# STMP3770 register map
Vendor: Freescale Semiconductor (NXP); Series: STMP37xx; File version: 1.0
CPU: other r0p0, little endian, no MPU, no FPU, 2 interrupt priority bits
Registers are 32-bit, read-write, reset 0x0 unless marked. A register's access mark holds for its fields unless they carry their own. Offsets are from the block's base; [hi:lo] are bit positions; {n}, {i} and the like mark numbered series.

## DIGCTL — STMP3770 DIGCTL 外设（数字控制/杂项）寄存器与位域中文描述。覆盖 slice 中全部寄存器与位域，名称逐字一致。
Base 0x8001C000
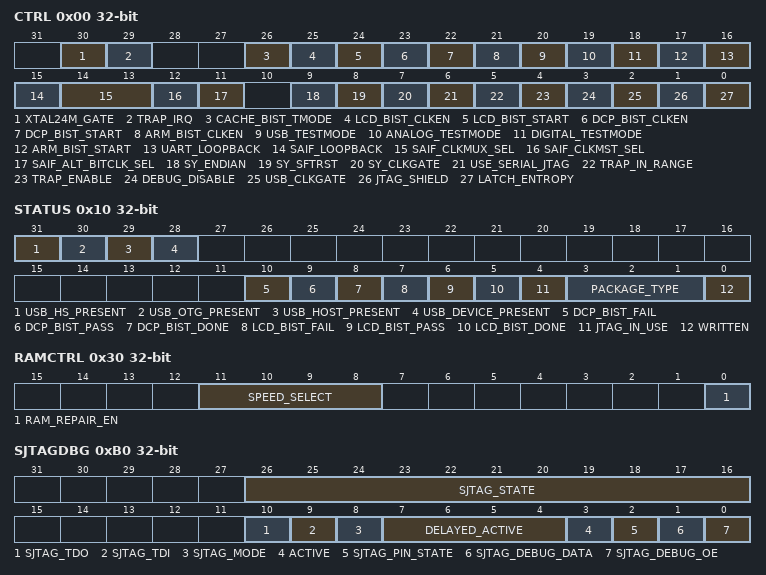
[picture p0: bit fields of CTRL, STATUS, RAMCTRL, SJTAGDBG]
0x00 CTRL — DIGCTL 控制寄存器，包含熵锁存、JTAG 防护、USB/SY 时钟门控、调试禁用、地址陷阱、串行 JTAG、SAIF/UART 环回、BIST 启动与时钟使能、测试模式、24MHz 晶振门控等控制位。
  [30] XTAL24M_GATE — 24MHz 晶振时钟门控控制位，置位关闭 XTAL24M 输出。
  [29] TRAP_IRQ — 地址陷阱中断状态/触发位。
  [26] CACHE_BIST_TMODE — Cache BIST 测试模式选择控制位。
  [25] LCD_BIST_CLKEN — LCD BIST 测试时钟使能控制位。
  [24] LCD_BIST_START — 置位启动 LCD 控制器 BIST。 PDF第7章标记bit 24为保留。
  [23] DCP_BIST_CLKEN — DCP BIST 测试时钟使能控制位。
  [22] DCP_BIST_START — 置位启动 DCP（显示协处理器）BIST。
  [21] ARM_BIST_CLKEN — ARM BIST 测试时钟使能控制位。
  [20] USB_TESTMODE — USB 测试模式使能控制位。
  [19] ANALOG_TESTMODE — 模拟测试模式使能控制位。
  [18] DIGITAL_TESTMODE — 数字测试模式使能控制位。
  [17] ARM_BIST_START — 置位启动 ARM 内核 BIST（内置自测试）。
  [16] UART_LOOPBACK — UART 环回模式：NORMAL=正常传输，LOOPIT=内部环回测试。
    0=NORMAL; 1=LOOPIT
  [15] SAIF_LOOPBACK — SAIF 环回模式：NORMAL=正常传输，LOOPIT=内部环回测试。
    0=NORMAL; 1=LOOPIT
  [14:13] SAIF_CLKMUX_SEL — SAIF 时钟多路选择：MBL_CLK_OUT/BL_CLK_OUT/M_CLK_OUT_BL_CLK_IN/BL_CLK_IN。
    0=MBL_CLK_OUT; 1=BL_CLK_OUT; 2=M_CLK_OUT_BL_CLK_IN; 3=BL_CLK_IN
  [12] SAIF_CLKMST_SEL — SAIF 主时钟源选择：SAIF1_MST=SAIF1 作主控，SAIF2_MST=SAIF2 作主控。
    0=SAIF1_MST; 1=SAIF2_MST
  [11] SAIF_ALT_BITCLK_SEL — SAIF 备用位时钟选择控制位。
  [9] SY_ENDIAN — SY 模块字节序选择控制位。 PDF第7章标记bit 9为保留。
  [8] SY_SFTRST — SY 模块软复位控制位。 PDF第7章标记bit 8为保留。
  [7] SY_CLKGATE — SY 模块时钟门控控制位。 PDF第7章标记bit 7为保留。
  [6] USE_SERIAL_JTAG — JTAG 接口选择：OLD_JTAG=传统 JTAG 接口，SERIAL_JTAG=串行 JTAG 接口。
    0=OLD_JTAG; 1=SERIAL_JTAG
  [5] TRAP_IN_RANGE — 置位表示陷阱范围有效（在 LOW/HIGH 地址之间），清零表示仅匹配单一地址。
  [4] TRAP_ENABLE — 使能地址陷阱功能，当访问落在陷阱范围内时触发异常。
  [3] DEBUG_DISABLE — 置位后禁用片上调试功能。
  [2] USB_CLKGATE — USB 控制器时钟门控：RUN=时钟运行，NO_CLKS=关闭时钟以节省功耗。
    0=RUN; 1=NO_CLKS
  [1] JTAG_SHIELD — JTAG 防护使能：NORMAL=正常模式，SHIELDS_UP=屏蔽模式（禁止外部 JTAG 访问）。
    0=NORMAL; 1=SHIELDS_UP
  [0] LATCH_ENTROPY — 置位后锁存当前 ENTROPY 寄存器值到 ENTROPY_LATCHED 寄存器。
0x10 STATUS ro — DIGCTL 状态寄存器，反映芯片封装类型、JTAG 占用状态、LCD/DCP BIST 结果及 USB 设备/主机/OTG/HS 存在性标志。
  [31] USB_HS_PRESENT — USB High-Speed 功能存在标志位。
  [30] USB_OTG_PRESENT — USB OTG 功能存在标志位。
  [29] USB_HOST_PRESENT — USB Host 功能存在标志位。
  [28] USB_DEVICE_PRESENT — USB Device 功能存在标志位。
  [10] DCP_BIST_FAIL — DCP BIST 测试失败标志位。
  [9] DCP_BIST_PASS — DCP BIST 测试通过标志位。
  [8] DCP_BIST_DONE — DCP BIST 测试完成标志位。
  [7] LCD_BIST_FAIL — LCD BIST 测试失败标志位。
  [6] LCD_BIST_PASS — LCD BIST 测试通过标志位。
  [5] LCD_BIST_DONE — LCD BIST 测试完成标志位。
  [4] JTAG_IN_USE — JTAG 接口当前正在被使用标志位。
  [3:1] PACKAGE_TYPE — 芯片封装类型标识编码。
  [0] WRITTEN — 芯片是否已被写入过（如熔丝/ROM 配置已写入）标志位。
0x20 HCLKCOUNT — HCLK 自由运行计数器，提供 32 位 AHB 总线时钟周期计数。
  [31:0] COUNT — HCLK 自由运行计数值，每拍递增，自然回绕。
0x30 RAMCTRL — 片内 RAM 控制寄存器，包含 RAM 修复使能与速度档位选择。
  [11:8] SPEED_SELECT — 片内 RAM 速度档位选择，用于调整时序裕量。
  [0] RAM_REPAIR_EN — 片内 RAM 修复功能使能控制位。
0x40 RAMREPAIR — 片内 RAM 修复地址寄存器，指定需要修复的 RAM 地址。
  [15:0] ADDR — RAM 修复目标地址。
0x50 ROMCTRL — 片内 ROM 控制寄存器，用于调整 ROM 读时序。
  [3:0] RD_MARGIN — ROM 读操作裕量（延迟/边距）设置值。
0x60 WRITEONCE — 软件一次性写寄存器，写入后不可再次修改（仅能在复位后重写）。
  [31:0] BITS — 32 位一次性写入数据位域。
0x90 ENTROPY — 熵寄存器，提供来自物理噪声源的随机数值。
  [31:0] VALUE — 实时熵值（随机数），由片上物理噪声源生成。
0xA0 ENTROPY_LATCHED — 熵锁存寄存器，保存由 LATCH_ENTROPY 触发锁存时的熵值。
  [31:0] VALUE — 锁存后的熵值快照，供软件读取固定随机数。
0xB0 SJTAGDBG — 串行 JTAG 调试寄存器，提供 SJTAG 接口的调试访问、状态监控与手动控制。
  [26:16] SJTAG_STATE — SJTAG 状态机当前状态编码。
  [10] SJTAG_TDO — SJTAG TDO（测试数据输出）信号值。
  [9] SJTAG_TDI — SJTAG TDI（测试数据输入）信号值。
  [8] SJTAG_MODE — SJTAG 模式选择控制位。
  [7:4] DELAYED_ACTIVE — SJTAG 激活延迟计数/延迟值。
  [3] ACTIVE — SJTAG 接口当前激活状态标志。
  [2] SJTAG_PIN_STATE — SJTAG 引脚当前状态。
  [1] SJTAG_DEBUG_DATA — SJTAG 调试数据输出值。
  [0] SJTAG_DEBUG_OE — SJTAG 调试数据输出使能控制位。
0xC0 MICROSECONDS — 微秒计数器寄存器，用于软件实现微秒级延时与计时。
  [31:0] VALUE — 微秒计数值，软件可读写，用于实现 us 级延时。
0xD0 DBGRD — 数字控制调试读测试寄存器，读取值为 DBG 寄存器值的按位取反。
  [31:0] COMPLEMENT — DBG 寄存器值的按位补码（取反），用于总线读测试验证。
0xE0 DBG — 数字控制调试寄存器，通用 32 位调试端口。
  [31:0] VALUE — 32 位调试数据值，只读，返回当前调试端口状态。
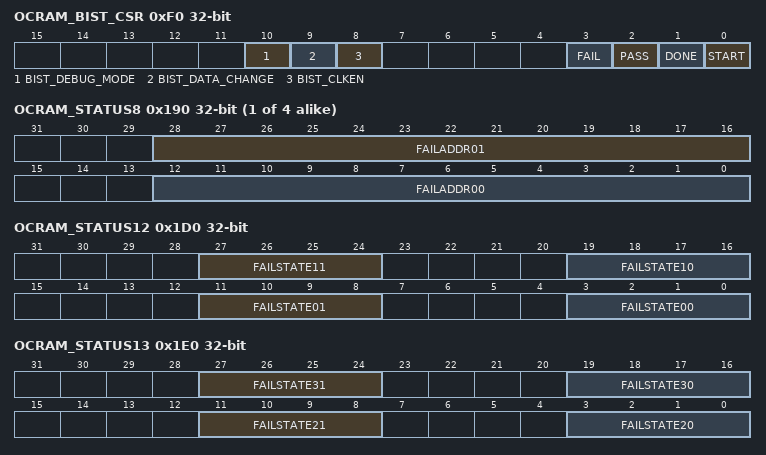
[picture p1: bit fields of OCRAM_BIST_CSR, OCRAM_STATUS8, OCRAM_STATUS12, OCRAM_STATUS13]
0xF0 OCRAM_BIST_CSR — SRAM BIST 控制与状态寄存器，用于启动和监控片内 SRAM 自测试。
  [10] BIST_DEBUG_MODE — SRAM BIST 调试模式使能控制位。
  [9] BIST_DATA_CHANGE — SRAM BIST 数据变化模式控制位。
  [8] BIST_CLKEN — SRAM BIST 测试时钟使能控制位。
  [3] FAIL — SRAM BIST 测试失败标志位。
  [2] PASS — SRAM BIST 测试通过标志位。
  [1] DONE — SRAM BIST 测试完成标志位。
  [0] START — 置位启动 SRAM BIST 测试。
0x110 OCRAM_STATUS0 — SRAM 状态寄存器 0，记录 BIST 失败时端口 0/数据 0 的故障数据。
  [31:0] FAILDATA00 — BIST 失败时端口 0、数据 0 的故障数据值。
0x120 OCRAM_STATUS1 — SRAM 状态寄存器 1，记录 BIST 失败时端口 0/数据 1 的故障数据。
  [31:0] FAILDATA01 — BIST 失败时端口 0、数据 1 的故障数据值。
0x130 OCRAM_STATUS2 — SRAM 状态寄存器 2，记录 BIST 失败时端口 1/数据 0 的故障数据。
  [31:0] FAILDATA10 — BIST 失败时端口 1、数据 0 的故障数据值。
0x140 OCRAM_STATUS3 — SRAM 状态寄存器 3，记录 BIST 失败时端口 1/数据 1 的故障数据。
  [31:0] FAILDATA11 — BIST 失败时端口 1、数据 1 的故障数据值。
0x150 OCRAM_STATUS4 — SRAM 状态寄存器 4，记录 BIST 失败时端口 2/数据 0 的故障数据。
  [31:0] FAILDATA20 — BIST 失败时端口 2、数据 0 的故障数据值。
0x160 OCRAM_STATUS5 — SRAM 状态寄存器 5，记录 BIST 失败时端口 2/数据 1 的故障数据。
  [31:0] FAILDATA21 — BIST 失败时端口 2、数据 1 的故障数据值。
0x170 OCRAM_STATUS6 — SRAM 状态寄存器 6，记录 BIST 失败时端口 3/数据 0 的故障数据。
  [31:0] FAILDATA30 — BIST 失败时端口 3、数据 0 的故障数据值。
0x180 OCRAM_STATUS7 — SRAM 状态寄存器 7，记录 BIST 失败时端口 3/数据 1 的故障数据。
  [31:0] FAILDATA31 — BIST 失败时端口 3、数据 1 的故障数据值。
{0x110+0x10*i} OCRAM_STATUS{i} (i=8..11) — SRAM 状态寄存器 {i}，记录 BIST 失败时端口 {i-8} 的故障地址。
  [28:16] FAILADDR{10i-79:02} — BIST 失败时端口 {i-8}、数据 1 的故障地址。
  [12:0] FAILADDR{10i-80:02} — BIST 失败时端口 {i-8}、数据 0 的故障地址。
0x1D0 OCRAM_STATUS12 — SRAM 状态寄存器 12，记录 BIST 失败时端口 0 和端口 1 的故障状态。
  [27:24] FAILSTATE11 — BIST 失败时端口 1、数据 1 的故障状态编码。
  [19:16] FAILSTATE10 — BIST 失败时端口 1、数据 0 的故障状态编码。
  [11:8] FAILSTATE01 — BIST 失败时端口 0、数据 1 的故障状态编码。
  [3:0] FAILSTATE00 — BIST 失败时端口 0、数据 0 的故障状态编码。
0x1E0 OCRAM_STATUS13 — SRAM 状态寄存器 13，记录 BIST 失败时端口 2 和端口 3 的故障状态。
  [27:24] FAILSTATE31 — BIST 失败时端口 3、数据 1 的故障状态编码。
  [19:16] FAILSTATE30 — BIST 失败时端口 3、数据 0 的故障状态编码。
  [11:8] FAILSTATE21 — BIST 失败时端口 2、数据 1 的故障状态编码。
  [3:0] FAILSTATE20 — BIST 失败时端口 2、数据 0 的故障状态编码。
0x290 SCRATCH0 — 数字控制 scratch 寄存器 0，供软件临时存储 32 位数据。
  [31:0] PTR — 32 位通用暂存数据值。
0x2A0 SCRATCH1 — 数字控制 scratch 寄存器 1，供软件临时存储 32 位数据。
  [31:0] PTR — 32 位通用暂存数据值。
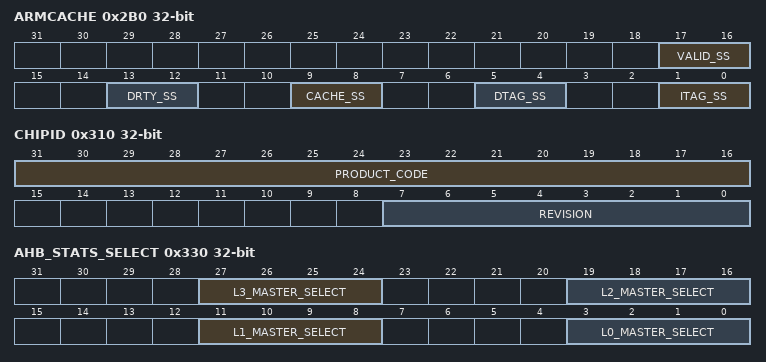
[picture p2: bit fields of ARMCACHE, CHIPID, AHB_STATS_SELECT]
0x2B0 ARMCACHE — ARM Cache 寄存器，反映 ARM926EJ-S 各 cache 子阵列的大小配置状态。
  [17:16] VALID_SS — Valid 位阵列大小状态（Valid sub-array size status）。
  [13:12] DRTY_SS — Dirty 位阵列大小状态（Dirty sub-array size status）。
  [9:8] CACHE_SS — Cache 数据阵列大小状态（Cache sub-array size status）。
  [5:4] DTAG_SS — 数据 Tag 阵列大小状态（DTAG sub-array size status）。
  [1:0] ITAG_SS — 指令 Tag 阵列大小状态（ITAG sub-array size status）。
0x2C0 DEBUG_TRAP_ADDR_LOW — 调试陷阱范围低地址寄存器，设定地址陷阱监控范围的下限。
  [31:0] ADDR — 陷阱范围低地址边界值。
0x2D0 DEBUG_TRAP_ADDR_HIGH — 调试陷阱范围高地址寄存器，设定地址陷阱监控范围的上限。
  [31:0] ADDR — 陷阱范围高地址边界值。
0x300 SGTL — SigmaTel 版权标识寄存器，读取返回固定版权标识码。
  [31:0] COPYRIGHT — SigmaTel 版权标识值。
0x310 CHIPID — 芯片版本与产品代码寄存器，用于识别芯片型号与硅片版本。
  [31:16] PRODUCT_CODE — 芯片产品代码，用于区分不同型号/变体。
  [7:0] REVISION — 芯片硅片版本号（Revision）。
0x330 AHB_STATS_SELECT — AHB 统计控制寄存器，选择各 AHB 层要监控的主设备。
  [27:24] L3_MASTER_SELECT — AHB 层 3 主设备选择位掩码：APBH=0x1，APBX=0x2，USB=0x4。
    1=APBH; 2=APBX; 4=USB
  [19:16] L2_MASTER_SELECT — AHB 层 2 主设备选择位掩码：ARM_D=0x1。
    1=ARM_D
  [11:8] L1_MASTER_SELECT — AHB 层 1 主设备选择位掩码：ARM_I=0x1。
    1=ARM_I
  [3:0] L0_MASTER_SELECT — AHB 层 0 主设备选择位掩码：ECC8=0x1，CRYPTO=0x2。
    1=ECC8; 2=CRYPTO
{0x340+0x30*i} L{i}_AHB_ACTIVE_CYCLES (i=0..3) — AHB 层 {i} 活跃周期计数器，记录选定主设备的总线传输周期数。
  [31:0] COUNT — AHB 层 {i} 活跃周期计数值。
{0x350+0x30*i} L{i}_AHB_DATA_STALLED (i=0..3) — AHB 层 {i} 数据停滞周期计数器，记录总线因等待而停滞的周期数。
  [31:0] COUNT — AHB 层 {i} 数据停滞周期计数值。
{0x360+0x30*i} L{i}_AHB_DATA_CYCLES (i=0..3) — AHB 层 {i} 有效数据周期计数器，记录总线上有效数据传输的周期数。
  [31:0] COUNT — AHB 层 {i} 有效数据周期计数值。
0x500 EMICLK_DELAY — EMI CLK/CLKN 延迟调整寄存器，用于微调外部存储器接口时钟相位。
  [4:0] NUM_TAPS — EMI 时钟延迟抽头数，控制 CLK/CLKN 输出延迟量。
